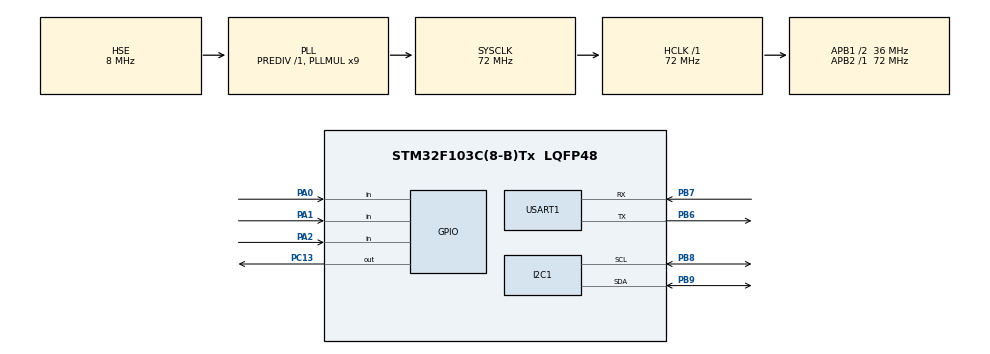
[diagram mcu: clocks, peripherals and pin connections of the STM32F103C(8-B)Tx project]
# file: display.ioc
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Dma.I2C1_TX.0.Direction=DMA_MEMORY_TO_PERIPH
Dma.I2C1_TX.0.Instance=DMA1_Channel6
Dma.I2C1_TX.0.MemDataAlignment=DMA_MDATAALIGN_BYTE
Dma.I2C1_TX.0.MemInc=DMA_MINC_ENABLE
Dma.I2C1_TX.0.Mode=DMA_NORMAL
Dma.I2C1_TX.0.PeriphDataAlignment=DMA_PDATAALIGN_BYTE
Dma.I2C1_TX.0.PeriphInc=DMA_PINC_DISABLE
Dma.I2C1_TX.0.Priority=DMA_PRIORITY_LOW
Dma.Request0=I2C1_TX
I2C1.OwnAddress=78
Mcu.Family=STM32F1
Mcu.Name=STM32F103C(8-B)Tx
Mcu.Package=LQFP48
NVIC.DMA1_Channel6_IRQn=true\:0\:0\:false\:false\:true\:false\:true
NVIC.I2C1_ER_IRQn=true\:0\:0\:false\:false\:true\:true\:true
NVIC.I2C1_EV_IRQn=true\:0\:0\:false\:false\:true\:true\:true
NVIC.PriorityGroup=NVIC_PRIORITYGROUP_4
NVIC.TIM3_IRQn=true\:0\:0\:false\:false\:true\:true\:true
NVIC.TIM4_IRQn=true\:0\:0\:false\:false\:true\:true\:true
NVIC.USART1_IRQn=true\:0\:0\:false\:false\:true\:true\:true
PA0-WKUP.GPIO_PuPd=GPIO_PULLUP
PA0-WKUP.Signal=GPIO_Input
PA1.GPIO_PuPd=GPIO_PULLUP
PA1.Signal=GPIO_Input
PA13.Mode=Serial_Wire
PA13.Signal=SYS_JTMS-SWDIO
PA14.Mode=Serial_Wire
PA14.Signal=SYS_JTCK-SWCLK
PA2.GPIO_PuPd=GPIO_PULLUP
PA2.Signal=GPIO_Input
PB6.Mode=Asynchronous
PB6.Signal=USART1_TX
PB7.Mode=Asynchronous
PB7.Signal=USART1_RX
PB8.Mode=I2C
PB8.Signal=I2C1_SCL
PB9.Mode=I2C
PB9.Signal=I2C1_SDA
PC13-TAMPER-RTC.Signal=GPIO_Output
PD0-OSC_IN.Mode=HSE-External-Oscillator
PD0-OSC_IN.Signal=RCC_OSC_IN
PD1-OSC_OUT.Mode=HSE-External-Oscillator
PD1-OSC_OUT.Signal=RCC_OSC_OUT
ProjectManager.HeapSize=0x200
ProjectManager.StackSize=0x400
ProjectManager.TargetToolchain=Makefile
RCC.AHBFreq_Value=72000000
RCC.APB1CLKDivider=RCC_HCLK_DIV2
RCC.APB1Freq_Value=36000000
RCC.APB1TimFreq_Value=72000000
RCC.APB2Freq_Value=72000000
RCC.APB2TimFreq_Value=72000000
RCC.HCLKFreq_Value=72000000
RCC.PLLMUL=RCC_PLL_MUL9
RCC.PLLSourceVirtual=RCC_PLLSOURCE_HSE
RCC.SYSCLKFreq_VALUE=72000000
RCC.SYSCLKSource=RCC_SYSCLKSOURCE_PLLCLK
RCC.USBFreq_Value=72000000
TIM3.Period=10000-1
TIM3.Prescaler=72-1
TIM4.AutoReloadPreload=TIM_AUTORELOAD_PRELOAD_ENABLE
TIM4.Period=1000-1
TIM4.Prescaler=72-1
USART1.VirtualMode=VM_ASYNC
VP_TIM3_VS_ClockSourceINT.Mode=Internal
VP_TIM4_VS_ClockSourceINT.Mode=Internal
board=custom

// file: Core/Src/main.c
/* USER CODE BEGIN Header */
/**
  ******************************************************************************
  * @file           : main.c
  * @brief          : Main program body
  ******************************************************************************
  * @attention
  *
  * <h2><center>&copy; Copyright (c) 2021 STMicroelectronics.
  * All rights reserved.</center></h2>
  *
  * This software component is licensed by ST under BSD 3-Clause license,
  * the "License"; You may not use this file except in compliance with the
  * License. You may obtain a copy of the License at:
  *                        opensource.org/licenses/BSD-3-Clause
  *
  ******************************************************************************
  */
/* USER CODE END Header */
#include "main.h"
#include "dma.h"
#include "i2c.h"
#include "tim.h"
#include "usart.h"
#include "gpio.h"

/* USER CODE BEGIN Includes */
#include "main_thread.h"
/* USER CODE END Includes */

void SystemClock_Config(void);

int main(void)
{

  /* MCU Configuration--------------------------------------------------------*/

  /* Reset of all peripherals, Initializes the Flash interface and the Systick. */
  HAL_Init();

  /* Configure the system clock */
  SystemClock_Config();

  /* Initialize all configured peripherals */
  MX_GPIO_Init();
  MX_DMA_Init();
  MX_TIM3_Init();
  MX_USART1_UART_Init();
  MX_I2C1_Init();
  MX_TIM4_Init();
  /* USER CODE BEGIN 2 */
    user_init();
/*
ssd1306_SetCursor(16,16);
ssd1306_WriteChar('A', Font_11x18, White);
ssd1306_SetCursor(32,16);
ssd1306_WriteChar('A', Font_6x8, White);
ssd1306_UpdateScreen();
*/
  /* USER CODE END 2 */

  /* Infinite loop */
  /* USER CODE BEGIN WHILE */
    while (1)
    {
        main_loop();
    /* USER CODE END WHILE */

    /* USER CODE BEGIN 3 */
//    ssd1306_TestAll();
#if 0
    for(uint8_t i = 0; i < 64; i++) {
        ssd1306_Line(0, i, 128, i, White);
        ssd1306_UpdateScreen();

        HAL_Delay(1000);
    }
    ssd1306_Fill(Black);
#endif

#if 0
//    ssd1306_TestLine();
    HAL_Delay(500);
#endif
//    ssd1306_WriteChar('A', Font_6x8, White);
/*
    for(uint8_t i = 0; i < 18; i++) {
        ssd1306_Line(0, i, 11, i, White);
    }
    ssd1306_SetCursor(0, 0);
    ssd1306_WriteChar('A', Font_11x18, Black);
    ssd1306_UpdateScreen();
    HAL_Delay(1000);

    ssd1306_SetCursor(0, 0);
    for(uint8_t i = 0; i < 18; i++) {
        ssd1306_Line(0, i, 11, i, Black);
    }
    ssd1306_SetCursor(0, 0);
    ssd1306_WriteChar('A', Font_11x18, White);
    ssd1306_UpdateScreen();
    HAL_Delay(1000);
*/
    }
  /* USER CODE END 3 */
}

void SystemClock_Config(void)
{
  RCC_OscInitTypeDef RCC_OscInitStruct = {0};
  RCC_ClkInitTypeDef RCC_ClkInitStruct = {0};

  /** Initializes the RCC Oscillators according to the specified parameters
  * in the RCC_OscInitTypeDef structure.
  */
  RCC_OscInitStruct.OscillatorType = RCC_OSCILLATORTYPE_HSE;
  RCC_OscInitStruct.HSEState = RCC_HSE_ON;
  RCC_OscInitStruct.HSEPredivValue = RCC_HSE_PREDIV_DIV1;
  RCC_OscInitStruct.HSIState = RCC_HSI_ON;
  RCC_OscInitStruct.PLL.PLLState = RCC_PLL_ON;
  RCC_OscInitStruct.PLL.PLLSource = RCC_PLLSOURCE_HSE;
  RCC_OscInitStruct.PLL.PLLMUL = RCC_PLL_MUL9;
  if (HAL_RCC_OscConfig(&RCC_OscInitStruct) != HAL_OK)
  {
    Error_Handler();
  }
  /** Initializes the CPU, AHB and APB buses clocks
  */
  RCC_ClkInitStruct.ClockType = RCC_CLOCKTYPE_HCLK|RCC_CLOCKTYPE_SYSCLK
                              |RCC_CLOCKTYPE_PCLK1|RCC_CLOCKTYPE_PCLK2;
  RCC_ClkInitStruct.SYSCLKSource = RCC_SYSCLKSOURCE_PLLCLK;
  RCC_ClkInitStruct.AHBCLKDivider = RCC_SYSCLK_DIV1;
  RCC_ClkInitStruct.APB1CLKDivider = RCC_HCLK_DIV2;
  RCC_ClkInitStruct.APB2CLKDivider = RCC_HCLK_DIV1;

  if (HAL_RCC_ClockConfig(&RCC_ClkInitStruct, FLASH_LATENCY_2) != HAL_OK)
  {
    Error_Handler();
  }
}

void Error_Handler(void)
{
  __disable_irq();
  while (1)
  {
  }
}

/************************ (C) COPYRIGHT STMicroelectronics *****END OF FILE****/
